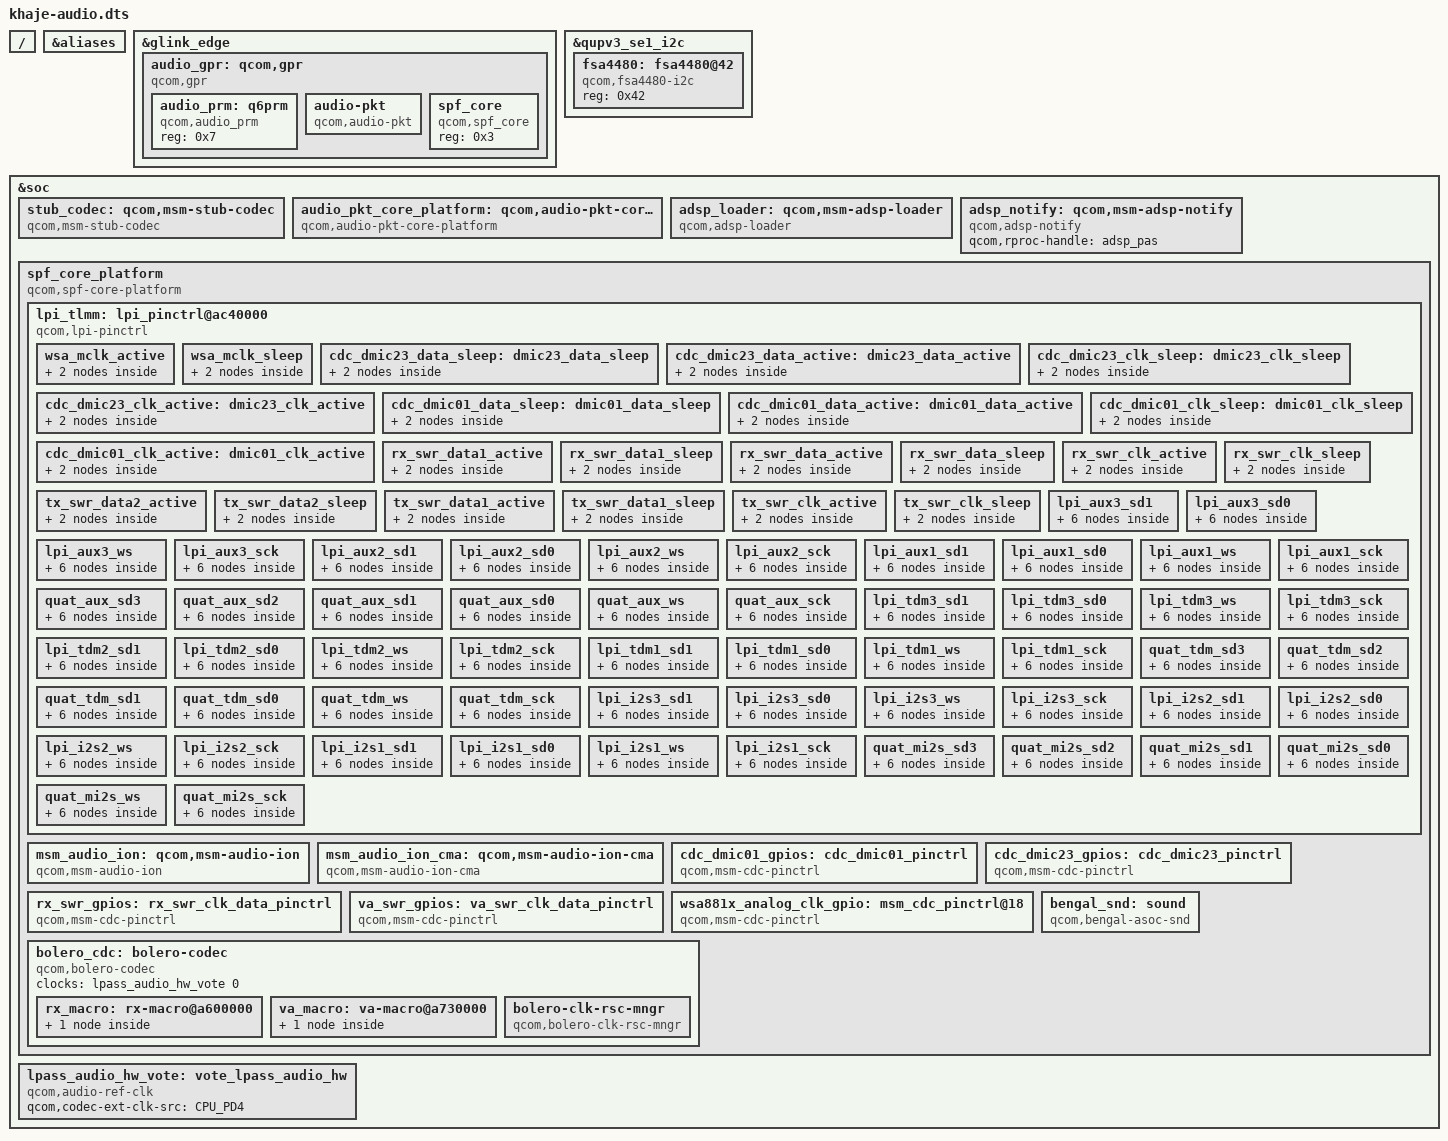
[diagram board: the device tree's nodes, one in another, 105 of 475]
// SPDX-License-Identifier: GPL-2.0-only
/*
 * khaje audio (SPF/AudioReach, bolero, LPASS) base overlay
 *
 * Reconstructed from the stock Redmi Note 13 4G (sapphire) vendor_boot DTB
 * (HyperOS OS2.0.215.0.VNHEUXM): the Qualcomm "audio-devicetree" techpack
 * devicetree is not published, so this overlay was rebuilt from the nodes
 * and properties it contributes to the merged khaje base DTB.  It is applied
 * onto qcom/khaje.dtb with fdtoverlay, as kernel_platform merge_dtbs.py does.
 */

/dts-v1/;
/plugin/;


/ {
	qcom,msm-id = <518 0x10000>, <586 0x10000>;
	qcom,board-id = <0 0>;
};

&aliases {
	swr1 = "/soc/spf_core_platform/bolero-codec/rx-macro@a600000/rx_swr_master";
	swr0 = "/soc/spf_core_platform/bolero-codec/va-macro@a730000/va_swr_master";
};

&glink_edge {
	audio_gpr: qcom,gpr {
		compatible = "qcom,gpr";
		qcom,glink-channels = "adsp_apps";
		qcom,intents = <512 20>;
		reg = <0x2>;
		audio_prm: q6prm {
			compatible = "qcom,audio_prm";
			reg = <0x7>;
		};
		audio-pkt {
			compatible = "qcom,audio-pkt";
			qcom,audiopkt-ch-name = "apr_audio_svc";
			reg = <0x17>;
		};
		spf_core {
			compatible = "qcom,spf_core";
			reg = <0x3>;
		};
	};
};

&qupv3_se1_i2c {
	fsa4480: fsa4480@42 {
		compatible = "qcom,fsa4480-i2c";
		reg = <0x42>;
	};
};

&soc {
	stub_codec: qcom,msm-stub-codec {
		compatible = "qcom,msm-stub-codec";
	};
	audio_pkt_core_platform: qcom,audio-pkt-core-platform {
		compatible = "qcom,audio-pkt-core-platform";
	};
	adsp_loader: qcom,msm-adsp-loader {
		qcom,adsp-state = <0>;
		qcom,rproc-handle = <&adsp_pas>;
		compatible = "qcom,adsp-loader";
		status = "ok";
	};
	adsp_notify: qcom,msm-adsp-notify {
		qcom,rproc-handle = <&adsp_pas>;
		compatible = "qcom,adsp-notify";
		status = "ok";
	};
	spf_core_platform: spf_core_platform {
		compatible = "qcom,spf-core-platform";
		lpi_tlmm: lpi_pinctrl@ac40000 {
			compatible = "qcom,lpi-pinctrl";
			reg = <0xa7c0000 0x0>;
			qcom,slew-reg = <0xa95a000 0x0>;
			qcom,gpios-count = <19>;
			gpio-controller;
			#gpio-cells = <2>;
			qcom,lpi-offset-tbl = <0 4096 8192 12288 16384 20480 24576 28672
			                       32768 36864 40960 45056 49152 53248 57344 61440
			                       0x10000 0x11000 0x12000>;
			qcom,lpi-slew-offset-tbl = <0 2 4 8 10 12 0 0
			                            0 0 0 0 0 0 0 0
			                            0 0 20>;
			clock-names = "lpass_audio_hw_vote";
			clocks = <&lpass_audio_hw_vote 0>;
			wsa_mclk_active: wsa_mclk_active {
				mux {
					function = "func1";
					pins = "gpio18";
				};
				config {
					output-high;
					bias-disable;
					drive-strength = <16>;
					pins = "gpio18";
				};
			};
			wsa_mclk_sleep: wsa_mclk_sleep {
				mux {
					function = "func1";
					pins = "gpio18";
				};
				config {
					bias-pull-down;
					drive-strength = <2>;
					pins = "gpio18";
				};
			};
			cdc_dmic23_data_sleep: dmic23_data_sleep {
				mux {
					function = "func1";
					pins = "gpio9";
				};
				config {
					input-enable;
					pull-down;
					drive-strength = <2>;
					pins = "gpio9";
				};
			};
			cdc_dmic23_data_active: dmic23_data_active {
				mux {
					function = "func1";
					pins = "gpio9";
				};
				config {
					input-enable;
					drive-strength = <8>;
					pins = "gpio9";
				};
			};
			cdc_dmic23_clk_sleep: dmic23_clk_sleep {
				mux {
					function = "func1";
					pins = "gpio8";
				};
				config {
					output-low;
					bias-disable;
					drive-strength = <2>;
					pins = "gpio8";
				};
			};
			cdc_dmic23_clk_active: dmic23_clk_active {
				mux {
					function = "func1";
					pins = "gpio8";
				};
				config {
					output-high;
					drive-strength = <8>;
					pins = "gpio8";
				};
			};
			cdc_dmic01_data_sleep: dmic01_data_sleep {
				mux {
					function = "func1";
					pins = "gpio7";
				};
				config {
					input-enable;
					pull-down;
					drive-strength = <2>;
					pins = "gpio7";
				};
			};
			cdc_dmic01_data_active: dmic01_data_active {
				mux {
					function = "func1";
					pins = "gpio7";
				};
				config {
					input-enable;
					drive-strength = <8>;
					pins = "gpio7";
				};
			};
			cdc_dmic01_clk_sleep: dmic01_clk_sleep {
				mux {
					function = "func1";
					pins = "gpio6";
				};
				config {
					output-low;
					bias-disable;
					drive-strength = <2>;
					pins = "gpio6";
				};
			};
			cdc_dmic01_clk_active: dmic01_clk_active {
				mux {
					function = "func1";
					pins = "gpio6";
				};
				config {
					output-high;
					drive-strength = <8>;
					pins = "gpio6";
				};
			};
			rx_swr_data1_active: rx_swr_data1_active {
				mux {
					function = "func1";
					pins = "gpio5";
				};
				config {
					bias-bus-hold;
					slew-rate = <3>;
					drive-strength = <10>;
					pins = "gpio5";
				};
			};
			rx_swr_data1_sleep: rx_swr_data1_sleep {
				mux {
					function = "func1";
					pins = "gpio5";
				};
				config {
					bias-pull-down;
					input-enable;
					drive-strength = <10>;
					pins = "gpio5";
				};
			};
			rx_swr_data_active: rx_swr_data_active {
				mux {
					function = "func1";
					pins = "gpio4";
				};
				config {
					bias-bus-hold;
					slew-rate = <3>;
					drive-strength = <10>;
					pins = "gpio4";
				};
			};
			rx_swr_data_sleep: rx_swr_data_sleep {
				mux {
					function = "func1";
					pins = "gpio4";
				};
				config {
					bias-pull-down;
					input-enable;
					drive-strength = <10>;
					pins = "gpio4";
				};
			};
			rx_swr_clk_active: rx_swr_clk_active {
				mux {
					function = "func1";
					pins = "gpio3";
				};
				config {
					bias-disable;
					slew-rate = <3>;
					drive-strength = <10>;
					pins = "gpio3";
				};
			};
			rx_swr_clk_sleep: rx_swr_clk_sleep {
				mux {
					function = "func1";
					pins = "gpio3";
				};
				config {
					bias-pull-down;
					input-enable;
					drive-strength = <10>;
					pins = "gpio3";
				};
			};
			tx_swr_data2_active: tx_swr_data2_active {
				mux {
					function = "func1";
					pins = "gpio2";
				};
				config {
					bias-bus-hold;
					slew-rate = <3>;
					drive-strength = <10>;
					pins = "gpio2";
				};
			};
			tx_swr_data2_sleep: tx_swr_data2_sleep {
				mux {
					function = "func1";
					pins = "gpio2";
				};
				config {
					bias-pull-down;
					input-enable;
					drive-strength = <10>;
					pins = "gpio2";
				};
			};
			tx_swr_data1_active: tx_swr_data1_active {
				mux {
					function = "func1";
					pins = "gpio1";
				};
				config {
					bias-bus-hold;
					slew-rate = <3>;
					drive-strength = <10>;
					pins = "gpio1";
				};
			};
			tx_swr_data1_sleep: tx_swr_data1_sleep {
				mux {
					function = "func1";
					pins = "gpio1";
				};
				config {
					bias-bus-hold;
					input-enable;
					drive-strength = <10>;
					pins = "gpio1";
				};
			};
			tx_swr_clk_active: tx_swr_clk_active {
				mux {
					function = "func1";
					pins = "gpio0";
				};
				config {
					bias-disable;
					slew-rate = <3>;
					drive-strength = <10>;
					pins = "gpio0";
				};
			};
			tx_swr_clk_sleep: tx_swr_clk_sleep {
				mux {
					bias-pull-down;
					input-enable;
					function = "func1";
					pins = "gpio0";
				};
				config {
					drive-strength = <10>;
					pins = "gpio0";
				};
			};
			lpi_aux3_sd1 {
				lpi_aux3_sd1_sleep: lpi_aux3_sd1_sleep {
					mux {
						function = "func1";
						pins = "gpio17";
					};
					config {
						input-enable;
						bias-pull-down;
						drive-strength = <2>;
						pins = "gpio17";
					};
				};
				lpi_aux3_sd1_active: lpi_aux3_sd1_active {
					mux {
						function = "func1";
						pins = "gpio17";
					};
					config {
						output-high;
						bias-disable;
						drive-strength = <8>;
						pins = "gpio17";
					};
				};
			};
			lpi_aux3_sd0 {
				lpi_aux3_sd0_sleep: lpi_aux3_sd0_sleep {
					mux {
						function = "func1";
						pins = "gpio16";
					};
					config {
						input-enable;
						bias-pull-down;
						drive-strength = <2>;
						pins = "gpio16";
					};
				};
				lpi_aux3_sd0_active: lpi_aux3_sd0_active {
					mux {
						function = "func1";
						pins = "gpio16";
					};
					config {
						output-high;
						bias-disable;
						drive-strength = <8>;
						pins = "gpio16";
					};
				};
			};
			lpi_aux3_ws {
				lpi_aux3_ws_sleep: lpi_aux3_ws_sleep {
					mux {
						function = "func1";
						pins = "gpio15";
					};
					config {
						input-enable;
						bias-pull-down;
						drive-strength = <2>;
						pins = "gpio15";
					};
				};
				lpi_aux3_ws_active: lpi_aux3_ws_active {
					mux {
						function = "func1";
						pins = "gpio15";
					};
					config {
						output-high;
						bias-disable;
						drive-strength = <8>;
						pins = "gpio15";
					};
				};
			};
			lpi_aux3_sck {
				lpi_aux3_sck_sleep: lpi_aux3_sck_sleep {
					mux {
						function = "func1";
						pins = "gpio14";
					};
					config {
						input-enable;
						bias-pull-down;
						drive-strength = <2>;
						pins = "gpio14";
					};
				};
				lpi_aux3_sck_active: lpi_aux3_sck_active {
					mux {
						function = "func1";
						pins = "gpio14";
					};
					config {
						output-high;
						bias-disable;
						drive-strength = <8>;
						pins = "gpio14";
					};
				};
			};
			lpi_aux2_sd1 {
				lpi_aux2_sd1_sleep: lpi_aux2_sd1_sleep {
					mux {
						function = "func2";
						pins = "gpio13";
					};
					config {
						input-enable;
						bias-pull-down;
						drive-strength = <2>;
						pins = "gpio13";
					};
				};
				lpi_aux2_sd1_active: lpi_aux2_sd1_active {
					mux {
						function = "func2";
						pins = "gpio13";
					};
					config {
						output-high;
						bias-disable;
						drive-strength = <8>;
						pins = "gpio13";
					};
				};
			};
			lpi_aux2_sd0 {
				lpi_aux2_sd0_sleep: lpi_aux2_sd0_sleep {
					mux {
						function = "func2";
						pins = "gpio12";
					};
					config {
						input-enable;
						bias-pull-down;
						drive-strength = <2>;
						pins = "gpio12";
					};
				};
				lpi_aux2_sd0_active: lpi_aux2_sd0_active {
					mux {
						function = "func2";
						pins = "gpio12";
					};
					config {
						output-high;
						bias-disable;
						drive-strength = <8>;
						pins = "gpio12";
					};
				};
			};
			lpi_aux2_ws {
				lpi_aux2_ws_sleep: lpi_aux2_ws_sleep {
					mux {
						function = "func1";
						pins = "gpio11";
					};
					config {
						input-enable;
						bias-pull-down;
						drive-strength = <2>;
						pins = "gpio11";
					};
				};
				lpi_aux2_ws_active: lpi_aux2_ws_active {
					mux {
						function = "func1";
						pins = "gpio11";
					};
					config {
						output-high;
						bias-disable;
						drive-strength = <8>;
						pins = "gpio11";
					};
				};
			};
			lpi_aux2_sck {
				lpi_aux2_sck_sleep: lpi_aux2_sck_sleep {
					mux {
						function = "func1";
						pins = "gpio10";
					};
					config {
						input-enable;
						bias-pull-down;
						drive-strength = <2>;
						pins = "gpio10";
					};
				};
				lpi_aux2_sck_active: lpi_aux2_sck_active {
					mux {
						function = "func1";
						pins = "gpio10";
					};
					config {
						output-high;
						bias-disable;
						drive-strength = <8>;
						pins = "gpio10";
					};
				};
			};
			lpi_aux1_sd1 {
				lpi_aux1_sd1_sleep: lpi_aux1_sd1_sleep {
					mux {
						function = "func2";
						pins = "gpio9";
					};
					config {
						input-enable;
						bias-pull-down;
						drive-strength = <2>;
						pins = "gpio9";
					};
				};
				lpi_aux1_sd1_active: lpi_aux1_sd1_active {
					mux {
						function = "func2";
						pins = "gpio9";
					};
					config {
						output-high;
						bias-disable;
						drive-strength = <8>;
						pins = "gpio9";
					};
				};
			};
			lpi_aux1_sd0 {
				lpi_aux1_sd0_sleep: lpi_aux1_sd0_sleep {
					mux {
						function = "func2";
						pins = "gpio8";
					};
					config {
						input-enable;
						bias-pull-down;
						drive-strength = <2>;
						pins = "gpio8";
					};
				};
				lpi_aux1_sd0_active: lpi_aux1_sd0_active {
					mux {
						function = "func2";
						pins = "gpio8";
					};
					config {
						output-high;
						bias-disable;
						drive-strength = <8>;
						pins = "gpio8";
					};
				};
			};
			lpi_aux1_ws {
				lpi_aux1_ws_sleep: lpi_aux1_ws_sleep {
					mux {
						function = "func2";
						pins = "gpio7";
					};
					config {
						input-enable;
						bias-pull-down;
						drive-strength = <2>;
						pins = "gpio7";
					};
				};
				lpi_aux1_ws_active: lpi_aux1_ws_active {
					mux {
						function = "func2";
						pins = "gpio7";
					};
					config {
						output-high;
						bias-disable;
						drive-strength = <8>;
						pins = "gpio7";
					};
				};
			};
			lpi_aux1_sck {
				lpi_aux1_sck_sleep: lpi_aux1_sck_sleep {
					mux {
						function = "func2";
						pins = "gpio6";
					};
					config {
						input-enable;
						bias-pull-down;
						drive-strength = <2>;
						pins = "gpio6";
					};
				};
				lpi_aux1_sck_active: lpi_aux1_sck_active {
					mux {
						function = "func2";
						pins = "gpio6";
					};
					config {
						output-high;
						bias-disable;
						drive-strength = <8>;
						pins = "gpio6";
					};
				};
			};
			quat_aux_sd3 {
				quat_aux_sd3_sleep: quat_aux_sd3_sleep {
					mux {
						function = "func3";
						pins = "gpio5";
					};
					config {
						input-enable;
						bias-pull-down;
						drive-strength = <2>;
						pins = "gpio5";
					};
				};
				quat_aux_sd3_active: quat_aux_sd3_active {
					mux {
						function = "func3";
						pins = "gpio5";
					};
					config {
						output-high;
						bias-disable;
						drive-strength = <8>;
						pins = "gpio5";
					};
				};
			};
			quat_aux_sd2 {
				quat_aux_sd2_sleep: quat_aux_sd2_sleep {
					mux {
						function = "func2";
						pins = "gpio4";
					};
					config {
						input-enable;
						bias-pull-down;
						drive-strength = <2>;
						pins = "gpio4";
					};
				};
				quat_aux_sd2_active: quat_aux_sd2_active {
					mux {
						function = "func2";
						pins = "gpio4";
					};
					config {
						output-high;
						bias-disable;
						drive-strength = <8>;
						pins = "gpio4";
					};
				};
			};
			quat_aux_sd1 {
				quat_aux_sd1_sleep: quat_aux_sd1_sleep {
					mux {
						function = "func2";
						pins = "gpio3";
					};
					config {
						input-enable;
						bias-pull-down;
						drive-strength = <2>;
						pins = "gpio3";
					};
				};
				quat_aux_sd1_active: quat_aux_sd1_active {
					mux {
						function = "func2";
						pins = "gpio3";
					};
					config {
						output-high;
						bias-disable;
						drive-strength = <8>;
						pins = "gpio3";
					};
				};
			};
			quat_aux_sd0 {
				quat_aux_sd0_sleep: quat_aux_sd0_sleep {
					mux {
						function = "func2";
						pins = "gpio2";
					};
					config {
						input-enable;
						bias-pull-down;
						drive-strength = <2>;
						pins = "gpio2";
					};
				};
				quat_aux_sd0_active: quat_aux_sd0_active {
					mux {
						function = "func2";
						pins = "gpio2";
					};
					config {
						output-high;
						bias-disable;
						drive-strength = <8>;
						pins = "gpio2";
					};
				};
			};
			quat_aux_ws {
				quat_aux_ws_sleep: quat_aux_ws_sleep {
					mux {
						function = "func2";
						pins = "gpio1";
					};
					config {
						input-enable;
						bias-pull-down;
						drive-strength = <2>;
						pins = "gpio1";
					};
				};
				quat_aux_ws_active: quat_aux_ws_active {
					mux {
						function = "func2";
						pins = "gpio1";
					};
					config {
						output-high;
						bias-disable;
						drive-strength = <8>;
						pins = "gpio1";
					};
				};
			};
			quat_aux_sck {
				quat_aux_sck_sleep: quat_aux_sck_sleep {
					mux {
						function = "func2";
						pins = "gpio0";
					};
					config {
						input-enable;
						bias-pull-down;
						drive-strength = <2>;
						pins = "gpio0";
					};
				};
				quat_aux_sck_active: quat_aux_sck_active {
					mux {
						function = "func2";
						pins = "gpio0";
					};
					config {
						output-high;
						bias-disable;
						drive-strength = <8>;
						pins = "gpio0";
					};
				};
			};
			lpi_tdm3_sd1 {
				lpi_tdm3_sd1_sleep: lpi_tdm3_sd1_sleep {
					mux {
						function = "func1";
						pins = "gpio17";
					};
					config {
						input-enable;
						bias-pull-down;
						drive-strength = <2>;
						pins = "gpio17";
					};
				};
				lpi_tdm3_sd1_active: lpi_tdm3_sd1_active {
					mux {
						function = "func1";
						pins = "gpio17";
					};
					config {
						output-high;
						bias-disable;
						drive-strength = <8>;
						pins = "gpio17";
					};
				};
			};
			lpi_tdm3_sd0 {
				lpi_tdm3_sd0_sleep: lpi_tdm3_sd0_sleep {
					mux {
						function = "func1";
						pins = "gpio16";
					};
					config {
						input-enable;
						bias-pull-down;
						drive-strength = <2>;
						pins = "gpio16";
					};
				};
				lpi_tdm3_sd0_active: lpi_tdm3_sd0_active {
					mux {
						function = "func1";
						pins = "gpio16";
					};
					config {
						output-high;
						bias-disable;
						drive-strength = <8>;
						pins = "gpio16";
					};
				};
			};
			lpi_tdm3_ws {
				lpi_tdm3_ws_sleep: lpi_tdm3_ws_sleep {
					mux {
						function = "func1";
						pins = "gpio15";
					};
					config {
						input-enable;
						bias-pull-down;
						drive-strength = <2>;
						pins = "gpio15";
					};
				};
				lpi_tdm3_ws_active: lpi_tdm3_ws_active {
					mux {
						function = "func1";
						pins = "gpio15";
					};
					config {
						output-high;
						bias-disable;
						drive-strength = <8>;
						pins = "gpio15";
					};
				};
			};
			lpi_tdm3_sck {
				lpi_tdm3_sck_sleep: lpi_tdm3_sck_sleep {
					mux {
						function = "func1";
						pins = "gpio14";
					};
					config {
						input-enable;
						bias-pull-down;
						drive-strength = <2>;
						pins = "gpio14";
					};
				};
				lpi_tdm3_sck_active: lpi_tdm3_sck_active {
					mux {
						function = "func1";
						pins = "gpio14";
					};
					config {
						output-high;
						bias-disable;
						drive-strength = <8>;
						pins = "gpio14";
					};
				};
			};
			lpi_tdm2_sd1 {
				lpi_tdm2_sd1_sleep: lpi_tdm2_sd1_sleep {
					mux {
						function = "func2";
						pins = "gpio13";
					};
					config {
						input-enable;
						bias-pull-down;
						drive-strength = <2>;
						pins = "gpio13";
					};
				};
				lpi_tdm2_sd1_active: lpi_tdm2_sd1_active {
					mux {
						function = "func2";
						pins = "gpio13";
					};
					config {
						output-high;
						bias-disable;
						drive-strength = <8>;
						pins = "gpio13";
					};
				};
			};
			lpi_tdm2_sd0 {
				lpi_tdm2_sd0_sleep: lpi_tdm2_sd0_sleep {
					mux {
						function = "func2";
						pins = "gpio12";
					};
					config {
						input-enable;
						bias-pull-down;
						drive-strength = <2>;
						pins = "gpio12";
					};
				};
				lpi_tdm2_sd0_active: lpi_tdm2_sd0_active {
					mux {
						function = "func2";
						pins = "gpio12";
					};
					config {
						output-high;
						bias-disable;
						drive-strength = <8>;
						pins = "gpio12";
					};
				};
			};
			lpi_tdm2_ws {
				lpi_tdm2_ws_sleep: lpi_tdm2_ws_sleep {
					mux {
						function = "func1";
						pins = "gpio11";
					};
					config {
						input-enable;
						bias-pull-down;
						drive-strength = <2>;
						pins = "gpio11";
					};
				};
				lpi_tdm2_ws_active: lpi_tdm2_ws_active {
					mux {
						function = "func1";
						pins = "gpio11";
					};
					config {
						output-high;
						bias-disable;
						drive-strength = <8>;
						pins = "gpio11";
					};
				};
			};
			lpi_tdm2_sck {
				lpi_tdm2_sck_sleep: lpi_tdm2_sck_sleep {
					mux {
						function = "func1";
						pins = "gpio10";
					};
					config {
						input-enable;
						bias-pull-down;
						drive-strength = <2>;
						pins = "gpio10";
					};
				};
				lpi_tdm2_sck_active: lpi_tdm2_sck_active {
					mux {
						function = "func1";
						pins = "gpio10";
					};
					config {
						output-high;
						bias-disable;
						drive-strength = <8>;
						pins = "gpio10";
					};
				};
			};
			lpi_tdm1_sd1 {
				lpi_tdm1_sd1_sleep: lpi_tdm1_sd1_sleep {
					mux {
						function = "func2";
						pins = "gpio9";
					};
					config {
						input-enable;
						bias-pull-down;
						drive-strength = <2>;
						pins = "gpio9";
					};
				};
				lpi_tdm1_sd1_active: lpi_tdm1_sd1_active {
					mux {
						function = "func2";
						pins = "gpio9";
					};
					config {
						output-high;
						bias-disable;
						drive-strength = <8>;
						pins = "gpio9";
					};
				};
			};
			lpi_tdm1_sd0 {
				lpi_tdm1_sd0_sleep: lpi_tdm1_sd0_sleep {
					mux {
						function = "func2";
						pins = "gpio8";
					};
					config {
						input-enable;
						bias-pull-down;
						drive-strength = <2>;
						pins = "gpio8";
					};
				};
				lpi_tdm1_sd0_active: lpi_tdm1_sd0_active {
					mux {
						function = "func2";
						pins = "gpio8";
					};
					config {
						output-high;
						bias-disable;
						drive-strength = <8>;
						pins = "gpio8";
					};
				};
			};
			lpi_tdm1_ws {
				lpi_tdm1_ws_sleep: lpi_tdm1_ws_sleep {
					mux {
						function = "func2";
						pins = "gpio7";
					};
					config {
						input-enable;
						bias-pull-down;
						drive-strength = <2>;
						pins = "gpio7";
					};
				};
				lpi_tdm1_ws_active: lpi_tdm1_ws_active {
					mux {
						function = "func2";
						pins = "gpio7";
					};
					config {
						output-high;
						bias-disable;
						drive-strength = <8>;
						pins = "gpio7";
					};
				};
			};
			lpi_tdm1_sck {
				lpi_tdm1_sck_sleep: lpi_tdm1_sck_sleep {
					mux {
						function = "func2";
						pins = "gpio6";
					};
					config {
						input-enable;
						bias-pull-down;
						drive-strength = <2>;
						pins = "gpio6";
					};
				};
				lpi_tdm1_sck_active: lpi_tdm1_sck_active {
					mux {
						function = "func2";
						pins = "gpio6";
					};
					config {
						output-high;
						bias-disable;
						drive-strength = <8>;
						pins = "gpio6";
					};
				};
			};
			quat_tdm_sd3 {
				quat_tdm_sd3_sleep: quat_tdm_sd3_sleep {
					mux {
						function = "func3";
						pins = "gpio5";
					};
					config {
						input-enable;
						bias-pull-down;
						drive-strength = <2>;
						pins = "gpio5";
					};
				};
				quat_tdm_sd3_active: quat_tdm_sd3_active {
					mux {
						function = "func3";
						pins = "gpio5";
					};
					config {
						output-high;
						bias-disable;
						drive-strength = <8>;
						pins = "gpio5";
					};
				};
			};
			quat_tdm_sd2 {
				quat_tdm_sd2_sleep: quat_tdm_sd2_sleep {
					mux {
						function = "func2";
						pins = "gpio4";
					};
					config {
						input-enable;
						bias-pull-down;
						drive-strength = <2>;
						pins = "gpio4";
					};
				};
				quat_tdm_sd2_active: quat_tdm_sd2_active {
					mux {
						function = "func2";
						pins = "gpio4";
					};
					config {
						output-high;
						bias-disable;
						drive-strength = <8>;
						pins = "gpio4";
					};
				};
			};
			quat_tdm_sd1 {
				quat_tdm_sd1_sleep: quat_tdm_sd1_sleep {
					mux {
						function = "func2";
						pins = "gpio3";
					};
					config {
						input-enable;
						bias-pull-down;
						drive-strength = <2>;
						pins = "gpio3";
					};
				};
				quat_tdm_sd1_active: quat_tdm_sd1_active {
					mux {
						function = "func2";
						pins = "gpio3";
					};
					config {
						output-high;
						bias-disable;
						drive-strength = <8>;
						pins = "gpio3";
					};
				};
			};
			quat_tdm_sd0 {
				quat_tdm_sd0_sleep: quat_tdm_sd0_sleep {
					mux {
						function = "func2";
						pins = "gpio2";
					};
					config {
						input-enable;
						bias-pull-down;
						drive-strength = <2>;
						pins = "gpio2";
					};
				};
				quat_tdm_sd0_active: quat_tdm_sd0_active {
					mux {
						function = "func2";
						pins = "gpio2";
					};
					config {
						output-high;
						bias-disable;
						drive-strength = <8>;
						pins = "gpio2";
					};
				};
			};
			quat_tdm_ws {
				quat_tdm_ws_sleep: quat_tdm_ws_sleep {
					mux {
						function = "func2";
						pins = "gpio1";
					};
					config {
						input-enable;
						bias-pull-down;
						drive-strength = <2>;
						pins = "gpio1";
					};
				};
				quat_tdm_ws_active: quat_tdm_ws_active {
					mux {
						function = "func2";
						pins = "gpio1";
					};
					config {
						output-high;
						bias-disable;
						drive-strength = <8>;
						pins = "gpio1";
					};
				};
			};
			quat_tdm_sck {
				quat_tdm_sck_sleep: quat_tdm_sck_sleep {
					mux {
						function = "func2";
						pins = "gpio0";
					};
					config {
						input-enable;
						bias-pull-down;
						drive-strength = <2>;
						pins = "gpio0";
					};
				};
				quat_tdm_sck_active: quat_tdm_sck_active {
					mux {
						function = "func2";
						pins = "gpio0";
					};
					config {
						output-high;
						bias-disable;
						drive-strength = <8>;
						pins = "gpio0";
					};
				};
			};
			lpi_i2s3_sd1 {
				lpi_i2s3_sd1_sleep: lpi_i2s3_sd1_sleep {
					mux {
						function = "func1";
						pins = "gpio17";
					};
					config {
						input-enable;
						bias-pull-down;
						drive-strength = <2>;
						pins = "gpio17";
					};
				};
				lpi_i2s3_sd1_active: lpi_i2s3_sd1_active {
					mux {
						function = "func1";
						pins = "gpio17";
					};
					config {
						output-high;
						bias-disable;
						drive-strength = <8>;
						pins = "gpio17";
					};
				};
			};
			lpi_i2s3_sd0 {
				lpi_i2s3_sd0_sleep: lpi_i2s3_sd0_sleep {
					mux {
						function = "func1";
						pins = "gpio16";
					};
					config {
						input-enable;
						bias-pull-down;
						drive-strength = <2>;
						pins = "gpio16";
					};
				};
				lpi_i2s3_sd0_active: lpi_i2s3_sd0_active {
					mux {
						function = "func1";
						pins = "gpio16";
					};
					config {
						output-high;
						bias-disable;
						drive-strength = <8>;
						pins = "gpio16";
					};
				};
			};
			lpi_i2s3_ws {
				lpi_i2s3_ws_sleep: lpi_i2s3_ws_sleep {
					mux {
						function = "func1";
						pins = "gpio15";
					};
					config {
						input-enable;
						bias-pull-down;
						drive-strength = <2>;
						pins = "gpio15";
					};
				};
				lpi_i2s3_ws_active: lpi_i2s3_ws_active {
					mux {
						function = "func1";
						pins = "gpio15";
					};
					config {
						output-high;
						bias-disable;
						drive-strength = <8>;
						pins = "gpio15";
					};
				};
			};
			lpi_i2s3_sck {
				lpi_i2s3_sck_sleep: lpi_i2s3_sck_sleep {
					mux {
						function = "func1";
						pins = "gpio14";
					};
					config {
						input-enable;
						bias-pull-down;
						drive-strength = <2>;
						pins = "gpio14";
					};
				};
				lpi_i2s3_sck_active: lpi_i2s3_sck_active {
					mux {
						function = "func1";
						pins = "gpio14";
					};
					config {
						output-high;
						bias-disable;
						drive-strength = <8>;
						pins = "gpio14";
					};
				};
			};
			lpi_i2s2_sd1 {
				lpi_i2s2_sd1_sleep: lpi_i2s2_sd1_sleep {
					mux {
						function = "func2";
						pins = "gpio13";
					};
					config {
						input-enable;
						bias-pull-down;
						drive-strength = <2>;
						pins = "gpio13";
					};
				};
				lpi_i2s2_sd1_active: lpi_i2s2_sd1_active {
					mux {
						function = "func2";
						pins = "gpio13";
					};
					config {
						output-high;
						bias-disable;
						drive-strength = <8>;
						pins = "gpio13";
					};
				};
			};
			lpi_i2s2_sd0 {
				lpi_i2s2_sd0_sleep: lpi_i2s2_sd0_sleep {
					mux {
						function = "func2";
						pins = "gpio12";
					};
					config {
						input-enable;
						bias-pull-down;
						drive-strength = <2>;
						pins = "gpio12";
					};
				};
				lpi_i2s2_sd0_active: lpi_i2s2_sd0_active {
					mux {
						function = "func2";
						pins = "gpio12";
					};
					config {
						output-high;
						bias-disable;
						drive-strength = <8>;
						pins = "gpio12";
					};
				};
			};
			lpi_i2s2_ws {
				lpi_i2s2_ws_sleep: lpi_i2s2_ws_sleep {
					mux {
						function = "func1";
						pins = "gpio11";
					};
					config {
						input-enable;
						bias-pull-down;
						drive-strength = <2>;
						pins = "gpio11";
					};
				};
				lpi_i2s2_ws_active: lpi_i2s2_ws_active {
					mux {
						function = "func1";
						pins = "gpio11";
					};
					config {
						output-high;
						bias-disable;
						drive-strength = <8>;
						pins = "gpio11";
					};
				};
			};
			lpi_i2s2_sck {
				lpi_i2s2_sck_sleep: lpi_i2s2_sck_sleep {
					mux {
						function = "func1";
						pins = "gpio10";
					};
					config {
						input-enable;
						bias-pull-down;
						drive-strength = <2>;
						pins = "gpio10";
					};
				};
				lpi_i2s2_sck_active: lpi_i2s2_sck_active {
					mux {
						function = "func1";
						pins = "gpio10";
					};
					config {
						output-high;
						bias-disable;
						drive-strength = <8>;
						pins = "gpio10";
					};
				};
			};
			lpi_i2s1_sd1 {
				lpi_i2s1_sd1_sleep: lpi_i2s1_sd1_sleep {
					mux {
						function = "func2";
						pins = "gpio9";
					};
					config {
						input-enable;
						bias-pull-down;
						drive-strength = <2>;
						pins = "gpio9";
					};
				};
				lpi_i2s1_sd1_active: lpi_i2s1_sd1_active {
					mux {
						function = "func2";
						pins = "gpio9";
					};
					config {
						output-high;
						bias-disable;
						drive-strength = <8>;
						pins = "gpio9";
					};
				};
			};
			lpi_i2s1_sd0 {
				lpi_i2s1_sd0_sleep: lpi_i2s1_sd0_sleep {
					mux {
						function = "func2";
						pins = "gpio8";
					};
					config {
						input-enable;
						bias-pull-down;
						drive-strength = <2>;
						pins = "gpio8";
					};
				};
				lpi_i2s1_sd0_active: lpi_i2s1_sd0_active {
					mux {
						function = "func2";
						pins = "gpio8";
					};
					config {
						output-high;
						bias-disable;
						drive-strength = <8>;
						pins = "gpio8";
					};
				};
			};
			lpi_i2s1_ws {
				lpi_i2s1_ws_sleep: lpi_i2s1_ws_sleep {
					mux {
						function = "func2";
						pins = "gpio7";
					};
					config {
						input-enable;
						bias-pull-down;
						drive-strength = <2>;
						pins = "gpio7";
					};
				};
				lpi_i2s1_ws_active: lpi_i2s1_ws_active {
					mux {
						function = "func2";
						pins = "gpio7";
					};
					config {
						output-high;
						bias-disable;
						drive-strength = <8>;
						pins = "gpio7";
					};
				};
			};
			lpi_i2s1_sck {
				lpi_i2s1_sck_sleep: lpi_i2s1_sck_sleep {
					mux {
						function = "func2";
						pins = "gpio6";
					};
					config {
						input-enable;
						bias-pull-down;
						drive-strength = <2>;
						pins = "gpio6";
					};
				};
				lpi_i2s1_sck_active: lpi_i2s1_sck_active {
					mux {
						function = "func2";
						pins = "gpio6";
					};
					config {
						output-high;
						bias-disable;
						drive-strength = <8>;
						pins = "gpio6";
					};
				};
			};
			quat_mi2s_sd3 {
				quat_mi2s_sd3_sleep: quat_mi2s_sd3_sleep {
					mux {
						function = "func3";
						pins = "gpio5";
					};
					config {
						input-enable;
						bias-pull-down;
						drive-strength = <2>;
						pins = "gpio5";
					};
				};
				quat_mi2s_sd3_active: quat_mi2s_sd3_active {
					mux {
						function = "func3";
						pins = "gpio5";
					};
					config {
						output-high;
						bias-disable;
						drive-strength = <8>;
						pins = "gpio5";
					};
				};
			};
			quat_mi2s_sd2 {
				quat_mi2s_sd2_sleep: quat_mi2s_sd2_sleep {
					mux {
						function = "func2";
						pins = "gpio4";
					};
					config {
						input-enable;
						bias-pull-down;
						drive-strength = <2>;
						pins = "gpio4";
					};
				};
				quat_mi2s_sd2_active: quat_mi2s_sd2_active {
					mux {
						function = "func2";
						pins = "gpio4";
					};
					config {
						output-high;
						bias-disable;
						drive-strength = <8>;
						pins = "gpio4";
					};
				};
			};
			quat_mi2s_sd1 {
				quat_mi2s_sd1_sleep: quat_mi2s_sd1_sleep {
					mux {
						function = "func2";
						pins = "gpio3";
					};
					config {
						input-enable;
						bias-pull-down;
						drive-strength = <2>;
						pins = "gpio3";
					};
				};
				quat_mi2s_sd1_active: quat_mi2s_sd1_active {
					mux {
						function = "func2";
						pins = "gpio3";
					};
					config {
						output-high;
						bias-disable;
						drive-strength = <8>;
						pins = "gpio3";
					};
				};
			};
			quat_mi2s_sd0 {
				quat_mi2s_sd0_sleep: quat_mi2s_sd0_sleep {
					mux {
						function = "func2";
						pins = "gpio2";
					};
					config {
						input-enable;
						bias-pull-down;
						drive-strength = <2>;
						pins = "gpio2";
					};
				};
				quat_mi2s_sd0_active: quat_mi2s_sd0_active {
					mux {
						function = "func2";
						pins = "gpio2";
					};
					config {
						output-high;
						bias-disable;
						drive-strength = <8>;
						pins = "gpio2";
					};
				};
			};
			quat_mi2s_ws {
				quat_mi2s_ws_sleep: quat_mi2s_ws_sleep {
					mux {
						function = "func2";
						pins = "gpio1";
					};
					config {
						input-enable;
						bias-pull-down;
						drive-strength = <2>;
						pins = "gpio1";
					};
				};
				quat_mi2s_ws_active: quat_mi2s_ws_active {
					mux {
						function = "func2";
						pins = "gpio1";
					};
					config {
						output-high;
						bias-disable;
						drive-strength = <8>;
						pins = "gpio1";
					};
				};
			};
			quat_mi2s_sck {
				quat_mi2s_sck_sleep: quat_mi2s_sck_sleep {
					mux {
						function = "func2";
						pins = "gpio0";
					};
					config {
						input-enable;
						bias-pull-down;
						drive-strength = <2>;
						pins = "gpio0";
					};
				};
				quat_mi2s_sck_active: quat_mi2s_sck_active {
					mux {
						function = "func2";
						pins = "gpio0";
					};
					config {
						output-high;
						bias-disable;
						drive-strength = <8>;
						pins = "gpio0";
					};
				};
			};
		};
		msm_audio_ion: qcom,msm-audio-ion {
			compatible = "qcom,msm-audio-ion";
			qcom,smmu-version = <2>;
			qcom,smmu-enabled;
			iommus = <&apps_smmu 449 0>;
			qcom,smmu-sid-mask = <0x0 0xf>;
			qcom,iommu-dma-addr-pool = <0x10000000 0x10000000>;
		};
		msm_audio_ion_cma: qcom,msm-audio-ion-cma {
			compatible = "qcom,msm-audio-ion-cma";
		};
		cdc_dmic01_gpios: cdc_dmic01_pinctrl {
			compatible = "qcom,msm-cdc-pinctrl";
			pinctrl-names = "aud_active", "aud_sleep";
			pinctrl-0 = <&cdc_dmic01_clk_active &cdc_dmic01_data_active>;
			pinctrl-1 = <&cdc_dmic01_clk_sleep &cdc_dmic01_data_sleep>;
			qcom,lpi-gpios;
			#gpio-cells = <0>;
		};
		cdc_dmic23_gpios: cdc_dmic23_pinctrl {
			compatible = "qcom,msm-cdc-pinctrl";
			pinctrl-names = "aud_active", "aud_sleep";
			pinctrl-0 = <&cdc_dmic23_clk_active &cdc_dmic23_data_active>;
			pinctrl-1 = <&cdc_dmic23_clk_sleep &cdc_dmic23_data_sleep>;
			qcom,lpi-gpios;
			#gpio-cells = <0>;
		};
		rx_swr_gpios: rx_swr_clk_data_pinctrl {
			compatible = "qcom,msm-cdc-pinctrl";
			pinctrl-names = "aud_active", "aud_sleep";
			pinctrl-0 = <&rx_swr_clk_active &rx_swr_data_active &rx_swr_data1_active>;
			pinctrl-1 = <&rx_swr_clk_sleep &rx_swr_data_sleep &rx_swr_data1_sleep>;
			qcom,lpi-gpios;
			#gpio-cells = <0>;
		};
		va_swr_gpios: va_swr_clk_data_pinctrl {
			compatible = "qcom,msm-cdc-pinctrl";
			pinctrl-names = "aud_active", "aud_sleep";
			pinctrl-0 = <&tx_swr_clk_active &tx_swr_data1_active &tx_swr_data2_active>;
			pinctrl-1 = <&tx_swr_clk_sleep &tx_swr_data1_sleep &tx_swr_data2_sleep>;
			qcom,lpi-gpios;
			qcom,chip-wakeup-reg = <0x3ca04c>;
			qcom,chip-wakeup-maskbit = <0>;
			qcom,chip-wakeup-default-val = <1>;
			#gpio-cells = <0>;
		};
		wsa881x_analog_clk_gpio: msm_cdc_pinctrl@18 {
			compatible = "qcom,msm-cdc-pinctrl";
			pinctrl-names = "aud_active", "aud_sleep";
			pinctrl-0 = <&wsa_mclk_active>;
			pinctrl-1 = <&wsa_mclk_sleep>;
			qcom,lpi-gpios;
			#gpio-cells = <0>;
		};
		bolero_cdc: bolero-codec {
			compatible = "qcom,bolero-codec";
			clock-names = "lpass_audio_hw_vote";
			clocks = <&lpass_audio_hw_vote 0>;
			rx_macro: rx-macro@a600000 {
				swr1: rx_swr_master {
				};
			};
			va_macro: va-macro@a730000 {
				swr0: va_swr_master {
				};
			};
			bolero-clk-rsc-mngr {
				compatible = "qcom,bolero-clk-rsc-mngr";
			};
		};
		bengal_snd: sound {
			compatible = "qcom,bengal-asoc-snd";
			qcom,mi2s-audio-intf = <0>;
			qcom,auxpcm-audio-intf = <0>;
			qcom,tdm-audio-intf = <0>;
			qcom,wcn-btfm = <0>;
			qcom,afe-rxtx-lb = <0>;
			fsa4480-i2c-handle = <&fsa4480>;
		};
	};
	lpass_audio_hw_vote: vote_lpass_audio_hw {
		compatible = "qcom,audio-ref-clk";
		qcom,codec-ext-clk-src = <&CPU_PD4>;
		#clock-cells = <1>;
	};
};
